# Polarfire SoC register map
Vendor: Microchip; File version: 1.0
CPU: Microchip PolarFire SoC 1.0, little endian
Registers are 32-bit, read-write, reset 0x0 unless marked. A register's access mark holds for its fields unless they carry their own. Offsets are from the block's base; [hi:lo] are bit positions; {n}, {i} and the like mark numbered series; 'fields as' and 'values as' point back to an identical list.

## GEM_A_LO (part 8 of 8) — GEM_A_LO Controller
Base 0x20110000
Same registers: GEM_B_LO 0x20112000, GEM_A_HI 0x28110000, GEM_B_HI 0x28112000
0x11EC emac_tsu_ptp_rx_nsec ro — PTP Event Frame Received Nanoseconds Register
  [29:0] TIMER — PTP Event Frame Received Nanoseconds. The register is updated with the value that the 1588 timer nanoseconds register held when the SFD of a PTP receive primary event crosses the MII interface. The actual update occurs when the GEM recognizes the frame as a PTP sync or delay_req frame. An interrupt is issued when the register is updated.
0x11F0 emac_tsu_peer_tx_sec ro — PTP Peer Event Frame Transmitted Seconds Register 31:0
  [31:0] TIMER — PTP Peer Event Frame Received Seconds. The register is updated with the value that the 1588 timer seconds register held when the SFD of a PTP transmit peer event crosses the MII interface. The actual update occurs when the GEM recognizes the frame as a PTP pdelay_req or pdelay_resp frame. An interrupt is issued when the register is updated.
0x11F4 emac_tsu_peer_tx_nsec ro — PTP Peer Event Frame Transmitted Nanoseconds Register
  [29:0] TIMER — PTP Peer Event Frame Transmitted Nanoseconds. The register is updated with the value that the 1588 timer nanoseconds register held when the SFD of a PTP transmit peer event crosses the MII interface. The actual update occurs when the GEM recognizes the frame as a PTP pdelay_req or pdelay_resp frame. An interrupt is issued when the register is updated.
0x11F8 emac_tsu_peer_rx_sec ro — PTP Peer Event Frame Received Seconds Register 31:0
  [31:0] TIMER — PTP Peer Event Frame Received Seconds. The register is updated with the value that the 1588 timer seconds register held when the SFD of a PTP receive peer event crosses the MII interface. The actual update occurs when the GEM recognizes the frame as a PTP pdelay_req or pdelay_resp frame. An interrupt is issued when the register is updated.
0x11FC emac_tsu_peer_rx_nsec ro — PTP Peer Event Frame Received Nanoseconds Register
  [29:0] TIMER — PTP Peer Event Frame Received Nanoseconds. The register is updated with the value that the 1588 timer nanoseconds register held when the SFD of a PTP receive peer event crosses the MII interface. The actual update occurs when the GEM recognizes the frame as a PTP pdelay_req or pdelay_resp frame. An interrupt is issued when the register is updated.
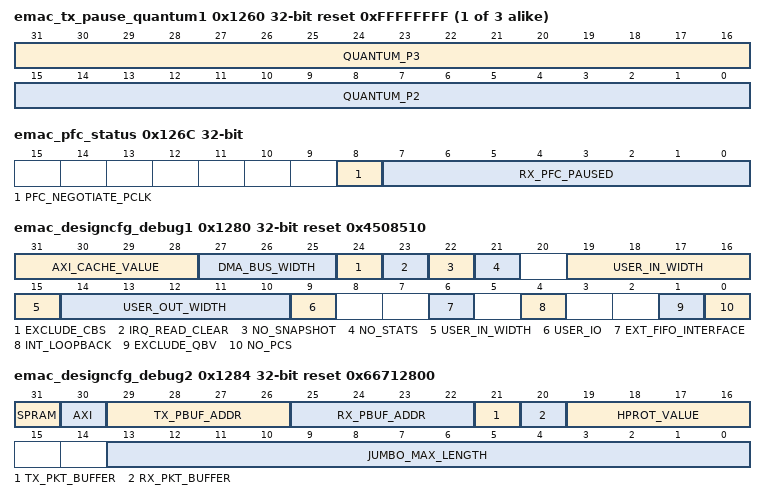
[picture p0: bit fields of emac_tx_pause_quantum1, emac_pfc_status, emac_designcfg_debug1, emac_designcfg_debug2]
{0x125C+4i} emac_tx_pause_quantum{i} reset 0xFFFFFFFF (i=1..3) — Transmit Pause Quantum Register {i}
  [31:16] QUANTUM_P{2i+1} — Transmit pause quantum - written with the pause quantum value for pause frame transmission of priority {2i+1}.
  [15:0] QUANTUM_P{2i} — Transmit pause quantum - written with the pause quantum value for pause frame transmission of priority {2i}.
0x126C emac_pfc_status ro — Priority Flow Control status register - indicates whether PFC has been negotiated and the current state of the PFC counters for each priority.
  [8] PFC_NEGOTIATE_PCLK — Set when PFC Priority Based Pause has been negotiated.
  [7:0] RX_PFC_PAUSED — Reflects the state of the rx_pfc_paused signals. Each bit in the vector corresponds to a priority indicated within the received PFC priority based pause frame. A bit is set when a PFC priority based pause frame has been received, and the associated priority pause time quantum is non-zero. The bit is cleared when the associated pause time has elapsed.
0x1270 emac_rx_lpi ro — Received LPI transitions
  [15:0] COUNT rw — Count of RX LPI transitions. A count of the number of times there is a transition from receiving normal idle to receiving low power idle. Cleared on read.
0x1274 emac_rx_lpi_time ro — Received LPI time
  [23:0] LPI_TIME rw — Time in LPI. This register increments once every 16 pclk cycles when the LPI indication bit 7 is set in the network status register. Cleared on read.
0x1278 emac_tx_lpi ro — Transmit LPI transitions
  [15:0] COUNT rw — Count of TX LPI transmissions. A count of the number of times the enable LPI transmission bit 19 goes from low to high in the network control register. Cleared on read.
0x127C emac_tx_lpi_time ro — Transmit LPI time
  [23:0] LPI_TIME rw — Time in LPI. This register increments once every 16 pclk cycles when the enable LPI transmission bit 19 is set in the network control register. Cleared on read.
0x1280 emac_designcfg_debug1 ro reset 0x4508510 — Design Configuration Register 1 - The GEM has many parameterisation options to configure the IP during compilation stage. This is achieved using Verilog define compiler directives in an include file called gem_defs.v. This configuration is readable through APB addressable designcfg_debug registers.
  [31:28] AXI_CACHE_VALUE — Takes the value of the 'gem_axi_awcache_value DEFINE
  [27:25] DMA_BUS_WIDTH — Takes the value of bits 7:5 of the 'gem_dma_bus_width DEFINE. So if the define is set to decimal 64 this will return binary 010.
  [24] EXCLUDE_CBS — Takes the value of the 'gem_exclude_cbs DEFINE.
  [23] IRQ_READ_CLEAR — Takes the value of the 'gem_irq_read_clear DEFINE
  [22] NO_SNAPSHOT — Takes the value of the 'gem_no_snapshot DEFINE
  [21] NO_STATS — Takes the value of the 'gem_no_stats DEFINE
  [19:15] USER_IN_WIDTH — Takes the value of the 'gem_user_in_width DEFINE or 1 if user_io not defined
  [14:10] USER_OUT_WIDTH — Takes the value of the 'gem_user_out_width DEFINE or 1 if user_io not defined
  [9] USER_IO — user_io not defined for the eMAC
  [6] EXT_FIFO_INTERFACE — Takes the value of the 'gem_ext_fifo_interface DEFINE
  [4] INT_LOOPBACK — Takes the value of the 'gem_int_loopback DEFINE
  [1] EXCLUDE_QBV — Takes the value of the 'gem_exclude_qbv DEFINE
  [0] NO_PCS — Takes the value of the 'gem_no_pcs DEFINE
0x1284 emac_designcfg_debug2 ro reset 0x66712800 — Design Configuration Register 2
  [31] SPRAM — Takes the value of the 'gem_spram DEFINE
  [30] AXI — Takes the value of the 'gem_axi DEFINE
  [29:26] TX_PBUF_ADDR — Takes the value of the 'gem_emac_tx_pbuf_addr DEFINE or zero if pbuf_address is decimal 16
  [25:22] RX_PBUF_ADDR — Takes the value of the 'gem_emac_rx_pbuf_addr DEFINE or zero if pbuf_address is decimal 16
  [21] TX_PKT_BUFFER — Takes the value of the 'gem_tx_pkt_buffer DEFINE
  [20] RX_PKT_BUFFER — Takes the value of the 'gem_rx_pkt_buffer DEFINE
  [19:16] HPROT_VALUE — Takes the value of the 'gem_hprot_value DEFINE
  [13:0] JUMBO_MAX_LENGTH — Takes the value of the 'gem_jumbo_max_length DEFINE
0x1288 emac_designcfg_debug3 ro reset 0x4000000 — Design Configuration Register 3
  [29:24] NUM_SPEC_ADD_FILTERS — Takes the value of the 'num_spec_add_filters DEFINE
0x128C emac_designcfg_debug4 ro — Design Configuration Register 4
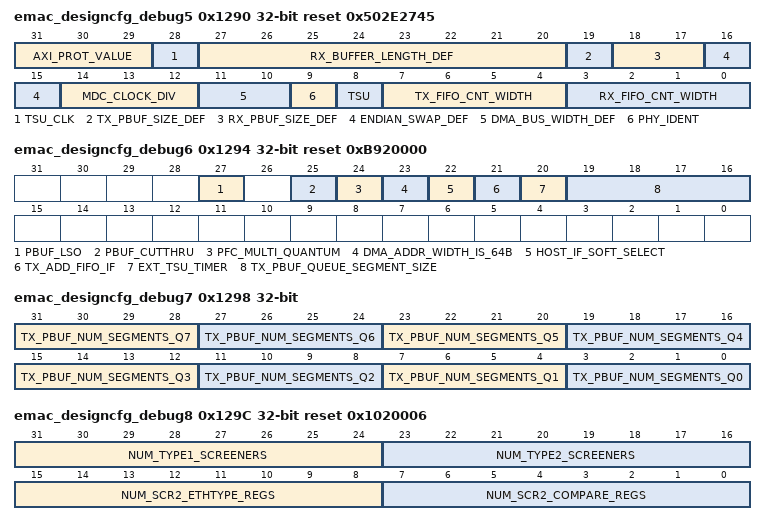
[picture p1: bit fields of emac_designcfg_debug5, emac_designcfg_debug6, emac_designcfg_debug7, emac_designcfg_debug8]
0x1290 emac_designcfg_debug5 ro reset 0x502E2745 — Design Configuration Register 5
  [31:29] AXI_PROT_VALUE — Takes the value of the edma_axi_prot_value parameter which is set by the 'gem_axi_prot_value DEFINE but will be zero if the FIFO interface has been configured
  [28] TSU_CLK — Takes the value of the 'gem_tsu_clk DEFINE
  [27:20] RX_BUFFER_LENGTH_DEF — Takes the value of the 'gem_rx_buffer_length_def DEFINE
  [19] TX_PBUF_SIZE_DEF — Takes the value of the edma_tx_pbuf_size_def parameter which is set by the 'gem_tx_pbuf_size_def DEFINE but will be zero if the FIFO inteface has been configured
  [18:17] RX_PBUF_SIZE_DEF — Takes the value of the 'gem_rx_pbuf_size_def DEFINE
  [16:15] ENDIAN_SWAP_DEF — Takes the value of the 'gem_endian_swap_def DEFINE
  [14:12] MDC_CLOCK_DIV — Takes the value of the 'gem_mdc_clock_div DEFINE
  [11:10] DMA_BUS_WIDTH_DEF — Takes the value of the 'gem_dma_bus_width_def DEFINE
  [9] PHY_IDENT — Indicates whether the top and bottom PHY_ID registers are present in the address map
  [8] TSU — Takes the value of the 'gem_tsu DEFINE
  [7:4] TX_FIFO_CNT_WIDTH — Takes the value of the 'gem_tx_fifo_cnt_width DEFINE
  [3:0] RX_FIFO_CNT_WIDTH — Takes the value of the 'gem_rx_fifo_cnt_width DEFINE
0x1294 emac_designcfg_debug6 ro reset 0xB920000 — Design Configuration Register 6
  [27] PBUF_LSO — Takes the value of the 'gem_pbuf_lso DEFINE
  [25] PBUF_CUTTHRU — Takes the value of the 'gem_pbuf_cutthru DEFINE
  [24] PFC_MULTI_QUANTUM — Takes the value of the 'gem_pfc_multi_quantum DEFINE
  [23] DMA_ADDR_WIDTH_IS_64B — Takes the value of the 'gem_dma_addr_width_is_64b DEFINE
  [22] HOST_IF_SOFT_SELECT — Takes the value of the 'gem_host_if_soft_select DEFINE
  [21] TX_ADD_FIFO_IF — Takes the value of the 'gem_tx_add_fifo_if DEFINE
  [20] EXT_TSU_TIMER — Set to one to indicate external TSU
  [19:16] TX_PBUF_QUEUE_SEGMENT_SIZE — Takes the value of the 'gem_tx_pbuf_queue_segment_size DEFINE
0x1298 emac_designcfg_debug7 ro — Design Configuration Register 7
  [4n+3:4n] TX_PBUF_NUM_SEGMENTS_Q{n} (n=1..7) — Takes the value of the 'gem_tx_pbuf_num_segments_q{n} DEFINE
  [3:0] TX_PBUF_NUM_SEGMENTS_Q0 — Takes the value of the edma_tx_pbuf_num_segments_q0 parameter which is set by the 'gem_tx_pbuf_num_segments_q0 DEFINE or is zero if priority queuing is not configured.
0x129C emac_designcfg_debug8 ro reset 0x1020006 — Design Configuration Register 8
  [31:24] NUM_TYPE1_SCREENERS — Set to 1 for the eMAC (express MAC)
  [23:16] NUM_TYPE2_SCREENERS — Set to 2 for the eMAC (express MAC)
  [15:8] NUM_SCR2_ETHTYPE_REGS — Set to 0 for the eMAC (express MAC)
  [7:0] NUM_SCR2_COMPARE_REGS — Set to 6 for the eMAC (express MAC)
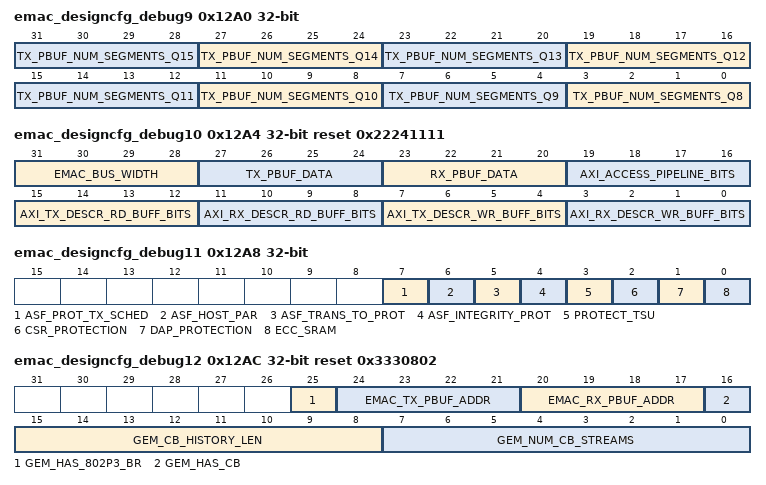
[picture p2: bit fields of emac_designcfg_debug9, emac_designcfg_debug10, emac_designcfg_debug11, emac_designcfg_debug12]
0x12A0 emac_designcfg_debug9 ro — Design Configuration Register 9
  [4n-29:4n-32] TX_PBUF_NUM_SEGMENTS_Q{n} (n=8..15) — Takes the value of the 'gem_tx_pbuf_num_segments_q{n} DEFINE
0x12A4 emac_designcfg_debug10 ro reset 0x22241111 — Design Configuration Register 10
  [31:28] EMAC_BUS_WIDTH — Takes the value of the 'gem_emac_bus_width DEFINE. 1 - The MAC has a datawidth of 32bits. 2 - The MAC has a datawidth of 64bits. 4 - The MAC has a datawidth of 128bits
  [27:24] TX_PBUF_DATA — Takes the value of the 'gem_tx_pbuf_data DEFINE. 1 - The TX DPRAM has a datawidth of 32bits. 2 - The TX DPRAM has a datawidth of 64bits. 4 - The TX DPRAM has a datawidth of 128bits
  [23:20] RX_PBUF_DATA — Takes the value of the 'gem_rx_pbuf_data DEFINE. 1 - The RX DPRAM has a datawidth of 32bits. 2 - The RX DPRAM has a datawidth of 64bits. 4 - RX The DPRAM has a datawidth of 128bits
  [19:16] AXI_ACCESS_PIPELINE_BITS — Takes the value of the edma_axi_access_pipeline_bits parameter which is set by the 'gem_axi_access_pipeline_bits DEFINE or is zero if the FIFO interface is configured.
  [15:12] AXI_TX_DESCR_RD_BUFF_BITS — Takes the value of the edma_axi_tx_descr_rd_buff_bits parameter which is set by the 'gem_axi_tx_descr_rd_buff_bits DEFINE or is zero if the FIFO interface is configured.
  [11:8] AXI_RX_DESCR_RD_BUFF_BITS — Takes the value of the edma_axi_rx_descr_rd_buff_bits parameter which is set by the 'gem_axi_rx_descr_rd_buff_bits DEFINE or is zero if the FIFO interface is configured.
  [7:4] AXI_TX_DESCR_WR_BUFF_BITS — Takes the value of the edma_axi_tx_descr_wr_buff_bits parameter which is set by the 'gem_axi_tx_descr_wr_buff_bits DEFINE or is zero if the FIFO interface is configured.
  [3:0] AXI_RX_DESCR_WR_BUFF_BITS — Takes the value of the edma_axi_rx_descr_wr_buff_bits parameter which is set by the 'gem_axi_rx_descr_wr_buff_bits DEFINE or is zero if the FIFO interface is configured.
0x12A8 emac_designcfg_debug11 ro — Design Configuration Register 11
  [7] ASF_PROT_TX_SCHED — Takes the value of the edma_asf_asf_prot_tx_sched parameter which is set by the 'gem_asf_prot_tx_sched DEFINE.
  [6] ASF_HOST_PAR — Takes the value of the edma_asf_host_par parameter which is set by the 'gem_asf_host_par DEFINE.
  [5] ASF_TRANS_TO_PROT — Takes the value of the edma_asf_trans_to_prot parameter which is set by the 'gem_asf_enable DEFINE.
  [4] ASF_INTEGRITY_PROT — Takes the value of the edma_asf_integrity_prot parameter which is set by the 'gem_asf_enable DEFINE.
  [3] PROTECT_TSU — akes the value of the edma_asf_prot_tsu parameter which is set by the 'gem_asf_prot_tsu DEFINE or is zero if no TSU is present.
  [2] CSR_PROTECTION — Takes the value of the edma_asf_csr_prot parameter which is set by the 'gem_asf_enable DEFINE.
  [1] DAP_PROTECTION — Takes the value of the edma_asf_dap_prot parameter which is set by the 'gem_asf_enable DEFINE.
  [0] ECC_SRAM — Takes the value of the edma_asf_ecc_sram parameter which is set by the 'gem_asf_ecc_sram DEFINE.
0x12AC emac_designcfg_debug12 ro reset 0x3330802 — Design Configuration Register 12
  [25] GEM_HAS_802P3_BR — A value of one indicates that gem_has_802p3_br is defined. If defined the configuration contains both an express MAC (eMAC) and a pre-emptable MAC (pMAC) to allow 802.3br frame pre-emption.
  [24:21] EMAC_TX_PBUF_ADDR — Takes the value of the 'gem_emac_tx_pbuf_addr DEFINE - this defines the size of the transmit SRAM for express MAC (eMAC) when 802.3br is configured - will be zero if emac_tx_pbuf_address is decimal 16
  [20:17] EMAC_RX_PBUF_ADDR — Takes the value of the 'gem_emac_rx_pbuf_addr DEFINE - this defines the size of the receive SRAM for express MAC (eMAC) when 802.3br is configured - will be zero if emac_tx_pbuf_address is decimal 16
  [16] GEM_HAS_CB — Indicates whether gem has 802.1CB/FRER configured
  [15:8] GEM_CB_HISTORY_LEN — Takes the value of the 'gem_seq_history_len DEFINE or 0x01 if undefined.
  [7:0] GEM_NUM_CB_STREAMS — Set to 2 for the eMAC (express MAC)
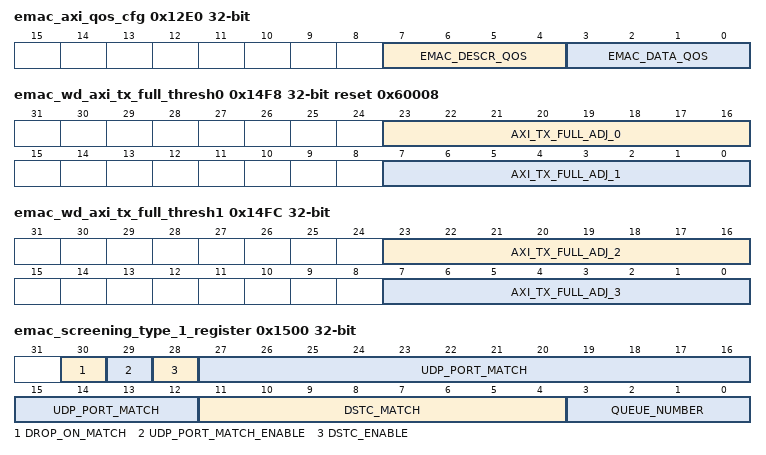
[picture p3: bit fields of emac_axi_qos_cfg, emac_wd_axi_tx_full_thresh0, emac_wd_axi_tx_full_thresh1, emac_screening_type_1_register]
0x12E0 emac_axi_qos_cfg — eMAC AXI Quality of Service register. This register is only present if AXI is configured. This register contains 8-bits to control driving of the ARQOS and AWQOS outputs (4-bits each). The lower four bits are for data accesses and the upper four bits are for descriptor accesses.
  [7:4] EMAC_DESCR_QOS — Determines what value to drive to the ARQOS and AWQOS outputs (4-bits each) for eMAC descriptor accesses.
  [3:0] EMAC_DATA_QOS — Determines what value to drive to the ARQOS and AWQOS outputs (4-bits each) for eMAC data accesses.
0x14BC emac_cbs_control — The IdleSlope value is defined as the rate of change of credit when a packet is waiting to be sent. This must not exceed the portTransmitRate which is dependent on the speed of operation, eg, portTransmitRate: 1Gb/s = 32'h07735940 (125 Mbytes/s), 100Mb/sec = 32'h017D7840 (25 Mnibbles/s), 10Mb/sec = 32'h002625A0 (2.5 Mnibbles/s). If 50% of bandwidth was to be allocated to a particular queue in 1Gb/sec mode then the IdleSlope value for that queue would be calculated as 32'h07735940/2. Note: Credit-Based Shaping should be disabled prior to updating the IdleSlope values. As another example, for a 1722 audio packet with a payload of 6 samples per channel, the packet size would be: 7 (preamble) + 1 (SFD) + 50 (packet header) + 6x4x2(payload) + 4 (CRC) = 110 bytes. For a rate of 8000 packets per second, the desired rate would 110 x 8000 bytes per second, so the programmed idleSlope value would be 880000 for a 1Gb/s connection, or 1760000 for a 100Mb/s or 10Mbs connection. See Figure 6.3 in the IEEE 1722 standard. In practice, the actual transmission rate will be vary slightly from that calculated. In this case, the idleSlope value should be recalibrated based on the variance between the measured and expected rate, and in this case very accurate transmission rates can be achieved. (The idleslope value is scaled by 2.5 in 2.5G operation and so the port transmit rate is the same for 1G and 2.5G.)
  [0] CBS_ENABLE_QUEUE_A — Enable Credit-Based Shaping on the highest priority queue (queue A). Write 1 to enable
0x14C0 emac_cbs_idleslope_q_a — Queue A is the highest priority queue. This is the highest indexed active queue, e.g. For a system with Q0 to Q7, this would be Q7 if all queues were active.
  [31:0] IDLESLOPE_A — IdleSlope value for queue A in bytes/sec for gigabit operation and nibbles/sec for 10/100 operation
0x14C4 emac_cbs_idleslope_q_b — Queue B is the 2nd highest priority queue. This is the second highest indexed active queue, e.g. For a system with Q0 to Q7, this would be Q6 if all queues were active.
  [31:0] IDLESLOPE_B — IdleSlope value for queue B in bytes/sec for gigabit operation and nibbles/sec for 10/100 operation
0x14C8 emac_upper_tx_q_base_addr — Upper 32 bits of transmit buffer descriptor queue base address.
  [31:0] UPPER_TX_Q_BASE_ADDR — Upper 32 bits of transmit buffer descriptor queue base address. Used when 64 bit addressing is enabled. (In releases earlier to 1p06f2 this register also affected the receive descriptor queue.)
0x14CC emac_tx_bd_control — Transmit buffer descriptor control register - this register determines which transmit frames, with time stamps reported in the buffer descriptor status field in extended buffer descriptor mode, set bit 23 in transmit buffer descriptor word 1.
  [5:4] TX_BD_TS_MODE — Transmit Descriptor Timestamp Insertion mode - bit 23 in transmit buffer descriptor word 1 when extended buffer descriptor mode is enabled,, : 00: Bit 23 always zero,, : 01: Bit 23 high for PTP Event Frames only,, : 10: Bit 23 high for all PTP Frames only,, : 11: Bit 23 always high
0x14D0 emac_rx_bd_control — Receive buffer descriptor control register - this register determines which receive frames have time stamps reported in the buffer descriptor status field
  [5:4] RX_BD_TS_MODE — Receive Descriptor Timestamp Insertion mode,, : 00: TS insertion disable,, : 01: TS inserted for PTP Event Frames only,, : 10: TS inserted for All PTP Frames only,, : 11: TS insertion for All Frames
0x14D4 emac_upper_rx_q_base_addr — Upper 32 bits of receive buffer descriptor queue base address.
  [31:0] UPPER_RX_Q_BASE_ADDR — Upper 32 bits of receive buffer descriptor queue base address. Used when 64 bit addressing is enabled.
0x14EC emac_wd_counter reset 0x7 — Hidden control register - do not alter
  [3:0] RX_BD_REREAD_TIMER — Controls counter used to retry receive descriptor reads (retries may occur if there was a resource error and there are frames waiting in the internal SRAM buffer to be off-loaded to host memory)
0x14F8 emac_wd_axi_tx_full_thresh0 reset 0x60008 — Hidden control register - do not alter
  [23:16] AXI_TX_FULL_ADJ_0 — AXI single port SRAM fine tuning
  [7:0] AXI_TX_FULL_ADJ_1 — AXI single port SRAM fine tuning
0x14FC emac_wd_axi_tx_full_thresh1 — Hidden control register - do not alter
  [23:16] AXI_TX_FULL_ADJ_2 — AXI single port SRAM fine tuning
  [7:0] AXI_TX_FULL_ADJ_3 — AXI single port SRAM fine tuning
0x1500 emac_screening_type_1_register — Screening type 1 registers are used to allocate up to 16 priority queues to received frames based on certain IP or UDP fields of incoming frames. Firstly, when DS/TC match enable is set (bit 28), the DS (Differentiated Services) field of the received IPv4 header or TC field (traffic class) of IPv6 headers are matched against bits 11:4. Secondly, when UDP port match enable is set (bit 29), the UDP Destination Port of the received UDP frame is matched against bits 27:12. Both UDP and DS/TC matching can be enabled simultaneously or individually. If a match is successful, then the queue value programmed in bits 3:0 is allocated to the frame. The required number of Type 1 screening registers is configured in the gem defines file. Up to 16 type 1 screening registers have been allocated APB address space between 0x500 and 0x53C. The bit mappings for these registers are as follows:
  [30] DROP_ON_MATCH — When set, if the frame matches it will be completely dropped. In this case the queue number is don't care.
  [29] UDP_PORT_MATCH_ENABLE
  [28] DSTC_ENABLE
  [27:12] UDP_PORT_MATCH
  [11:4] DSTC_MATCH
  [3:0] QUEUE_NUMBER — Queue Number (0 to 15)
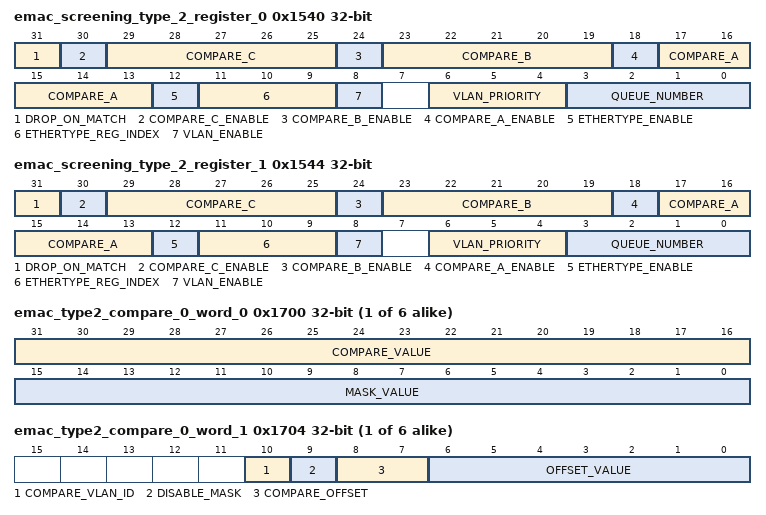
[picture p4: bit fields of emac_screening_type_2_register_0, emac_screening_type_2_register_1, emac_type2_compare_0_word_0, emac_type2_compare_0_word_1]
0x1540 emac_screening_type_2_register_0 — Screener Type 2 match registers allow a screen to be configured that is the combination of all or any of the following comparisons:, :1) An enabled VLAN Priority. A VLAN Priority match will be performed if the VLAN priority enable is set. The extracted priority field in the VLAN header is compared against 3 bits within the screener type 2 register itself., :2) An enabled EtherType., :3) An enabled Field Compare A. , :4) An enabled Field Compare B. , :5) An enabled Field Compare C. , :All enabled comparisons are ANDed together to form the overall type 2 screener match. If a match is successful, then the queue value programmed in bits 3:0 is allocated to the frame. The required number of Type 2 screening registers is configured in the gem defines file. Up to 16 type 2 screening registers have been allocated APB address space between 0x540 and 0x57C. The bit mappings for these registers are as follows:
  [31] DROP_ON_MATCH — When set, if the frame matches it will be completely dropped. In this case the queue number is don't care.
  [30] COMPARE_C_ENABLE
  [29:25] COMPARE_C — Compare C - Index to screener type 2 Compare register
  [24] COMPARE_B_ENABLE
  [23:19] COMPARE_B — Compare B - Index to screener type 2 Compare register
  [18] COMPARE_A_ENABLE
  [17:13] COMPARE_A — Compare A - Index to screener type 2 Compare register
  [12] ETHERTYPE_ENABLE
  [11:9] ETHERTYPE_REG_INDEX — Index to screener type 2 EtherType register
  [8] VLAN_ENABLE
  [6:4] VLAN_PRIORITY
  [3:0] QUEUE_NUMBER — Queue Number (0 to 15)
0x1544 emac_screening_type_2_register_1 — Screener Type 2 match registers allow a screen to be configured that is the combination of all or any of the following comparisons:, :1) An enabled VLAN Priority. A VLAN Priority match will be performed if the VLAN priority enable is set. The extracted priority field in the VLAN header is compared against 3 bits within the screener type 2 register itself., :2) An enabled EtherType., :3) An enabled Field Compare A. , :4) An enabled Field Compare B. , :5) An enabled Field Compare C. , :All enabled comparisons are ANDed together to form the overall type 2 screener match. If a match is successful, then the queue value programmed in bits 3:0 is allocated to the frame. The required number of Type 2 screening registers is configured in the gem defines file. Up to 16 type 2 screening registers have been allocated APB address space between 0x540 and 0x57C. The bit mappings for these registers are as follows:
  fields as emac_screening_type_2_register_0
0x1580 emac_tx_sched_ctrl — This register controls the transmit scheduling algorithm the user can select for the eMAC.
  [1:0] TX_SCHED — Transmit scheduling algorithm., : 00 : Normal Priority, : 01 : CBS Enabled only valid if CBS capability selected., : 10 : DWRR Enabled, : 11 : ETS Enabled
0x1590 emac_bw_rate_limit — This register holds the DWRR weighting value or the ETS bandwidth percentage value used by the transmit scheduler for the eMAC.
  [7:0] EMAC_DWRR_ETS_WEIGHT — DWRR Weighting / ETS Bandwidth Allocation for the eMAC
0x15A0 emac_tx_q_seg_alloc_q_lower — There should be no need to change this register for the eMAC.
  [2:0] SEGMENT_ALLOC — Number of segments allocated. This should be entered as a log 2, for example entering a value of 2 would grant 4 segments. A maximum of 16 segments can be granted.
{0x1700+8i} emac_type2_compare_{i}_word_0 (i=0..5) — Compare A, B and C fields of the screener type 2 match register are pointers to a pool of up to 32 compare registers. If enabled the compare is true if the data at the OFFSET into the frame, ANDed with the MASK Value if the mask is enabled, is equal to the COMPARE Value. Either a 16 bit comparison or a 32 bit comparison is done. This selection is made via the associated compare word1 register bit 9. If a 16 bit comparison is selected, then a 16 bit mask is also available to the user to select which bits should be compared. If the 32 bit compare option is selected, then no mask is available. The byte at the OFFSET number of bytes from the index start is compared thru bits 7:0 of the configured VALUE. The byte at the OFFSET number of bytes + 1 from the index start is compared thru bits 15:8 of the configured VALUE and so on. The OFFSET can be configured to be from 0 to 127 bytes from either the start of the frame, the byte following the therType field (last EtherType in the header if the frame is VLAN tagged), the byte following the IP header (IPv4 or IPv6) or from the byte following the start of the TCP/UDP header. The required number of Type 2 screening registers up to a maximum of 32 is configurable in the gem defines file and have been allocated APB address space between 0x700 and 0x7fc. Note. when using RX Partial Store and Forward mode and priority queues, the frame offset must be less than the Partial Store and Forward watermark. If the offset is higher than the watermark value it's not possible to identify the priority queue before the frame is sent to the AMBA interface, and an incorrect priority queue may be used.
  [31:16] COMPARE_VALUE — 2 byte Compare Value., :, :If bit 9 of the associated compare_word1 register is set, then the byte stored in bits [23:16] is compared against the byte in the received frame from the selected offset+2 and the byte stored in bits [31:24] is compared against the byte in the received frame from the selected offset+3., :, :If bit 9 of the associated compare_word1 register is clear, then the byte stored in bits [23:16] is compared against the byte in the received frame from the selected offset+0 and the byte stored in bits [31:24] is compared against the byte in the received frame from the selected offset+1., :
  [15:0] MASK_VALUE — These bits can be either a 2 byte mask field or an additional 2 byte Compare Value. , :, :If bit 9 of the associated compare_word1 register is set, then the byte stored in bits [7:0] is compared against the byte in the received frame from the selected offset+0 and the byte stored in bits [15:8] is compared against the byte in the received frame from the selected offset+1. , :, :If bit 9 of the associated compare_word1 register is clear, these bits become a direct 2-byte mask for the 2-byte compare register in bits [31:16]. A value of zero in a mask bit masks the corresponding data bit, a value of 1 enables the comparison.
{0x1704+8i} emac_type2_compare_{i}_word_1 (i=0..5) — Type2 Compare Word 1
  [10] COMPARE_VLAN_ID — If set bits 9, 8 and 6:0 must be 0 and bit 7 of compare_offset is used as follows:, :0 Compare C-TAG VID (VLAN has EtherType of 0x8100), :1 Compare S-TAG VID comparison (VLAN has EtherType of the value in the stacked VLAN register at 0x00C0), :Note the byte order is such that if 81 00 00 20 is received to indicate a C-TAG frame with VID 020 0x00200FFF would be written to the compare register. So in the special case of VLAN comparison the last byte received is the least significant byte in the compare register
  [9] DISABLE_MASK — This bit is used to control whether the compare register word_0 contains a 4-byte compare value, or a 2-byte compare value with a 2-byte mask value., :1 - 4-byte compare value, :0 - 2-byte compare, 2-byte mask
  [8:7] COMPARE_OFFSET — Compare byte offset., :00 : Offset from beginning of the frame., :01 : Offset from byte after Ether Type., :10 : Offset from byte following end of IP header., :11 : Offset from byte following end of TCP/UDP header
  [6:0] OFFSET_VALUE — Offset value in bytes
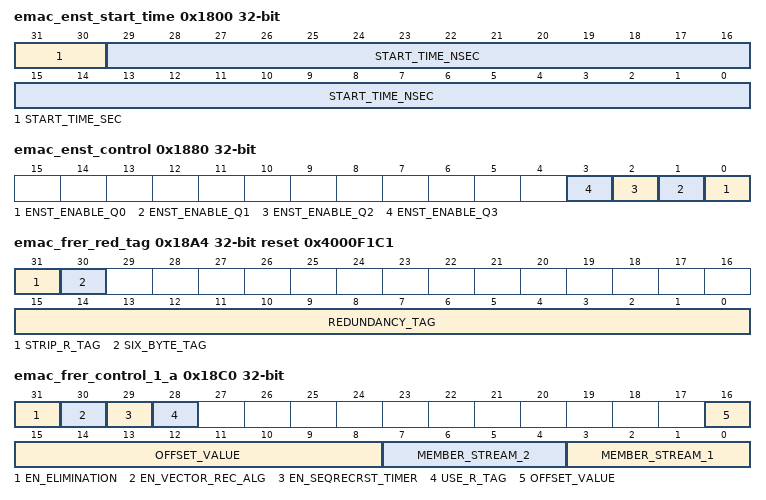
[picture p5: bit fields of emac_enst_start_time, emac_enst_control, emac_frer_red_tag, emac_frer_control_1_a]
0x1800 emac_enst_start_time — This register sets the absolute time at which queue q0 starts EnST transmit scheduling
  [31:30] START_TIME_SEC — Bits 31:30 of the start time (seconds field), for q0
  [29:0] START_TIME_NSEC — Bits 29:0 of the start time (nanoseconds field), for q0
0x1820 emac_enst_on_time reset 0x1FFFF — This register sets the time period for which queue q0 is to be open, (on_time_nsec), this register has to be written according to the speed mode as:, : ||1Gbps or 2.5Gbps|| : on_time = on_time_nsec/8, : ||100Mbps|| : on_time = on_time_nsec/80, : ||10Mbps|| : on_time = on_time_nsec/800
  [16:0] ON_TIME — on_time, for q0
0x1840 emac_enst_off_time — This register sets the time period for which queue q0 is to be blocked, (off_time_nsec), this register has to be written according to the speed mode as:, : ||1Gbps or 2.5Gbps|| => off_time = off_time_nsec/8, : ||100Mbps|| => off_time = off_time_nsec/80, : ||10Mbps|| => off_time = off_time_nsec/800
  [16:0] OFF_TIME — Off_time, for q0
0x1880 emac_enst_control — Enhancement for Scheduled Traffic control register. EnST scheduling can only be applied to a maximum number of 8 queues. If 802.3br operation has been configured and both an eMAC and pMAC are present then the eMAC only supports a single queue and EnST is enabled on the eMAC by writing to bit 0 of emac_enst_control.
  [n] ENST_ENABLE_Q{n} (n=0..3) — Set to enable enhanced scheduler traffic (ENST), for q{n}
0x18A0 emac_frer_timeout — FRER timeout register. This determines when the sequence recovery reset timers are reset and is used by all of the configured CB streams. It is programmed as a count of 8192 rx_clk periods. 8192 rx_clk periods is 65.536 microseconds at gigabit speeds and 327.68 microseconds at 100M speeds, this allows a max timeout value of about 4 seconds at gigabit speeds - for test purposes if bit 12 (retry_test) is set in the network configuration register at 0x004 then the timeout value just becomes a count of rx_clk periods (ie a speed-up of 8192 in the time-out process).
  [15:0] TIMEOUT — Count of 8192 rx_clk periods.
0x18A4 emac_frer_red_tag reset 0x4000F1C1 — FRER redundancy tag register. This defines the Ethertype used to identify the R-TAG (redundancy tag) and contains a control bit to enable stripping of the R-TAG from received frames. IEEE 802.1CB has defined the value of this Ethertype to be 0xF1C1. Whether or not a particular stream uses the redundancy tag to locate the sequence number is determined by bit 28 in that streams control register.
  [31] STRIP_R_TAG — If set the redundancy tag is stripped from received frames. If this bit is set then the receive octet counters reflect post deletion frame size so the FRER functionality is transparent to higher level management if the stripping function is enabled. If the statistics counters need to reflect the actual number of octets received, then the stripping functionality should be disabled.
  [30] SIX_BYTE_TAG — Draft 2.4 and earlier drafts of the 802.1CB standard defined a four-byte redundancy tag. Drafts 2.5 and later specified a six-byte tag. Releases 1p10 and 1p11 were implemented in accordance with draft 2.4 of the standard. Set this bit to zero to inter-operate with implementations that use a four-byte tag.
  [15:0] REDUNDANCY_TAG — Ethertype value used to identify the redundancy tag (R-TAG).
0x18C0 emac_frer_control_1_a — FRER control register A
  [31] EN_ELIMINATION — Enable 802.1CB elimination of received frames
  [30] EN_VECTOR_REC_ALG — Enable 802.1CB vector recovery algorithm, : 0 enables the match recovery algorithm, : 1 enables the vector recovery algorithm, :This bit should only be changed when bit 31 en_elimination is low
  [29] EN_SEQRECRST_TIMER — Enable 802.1CB sequence recovery reset timer - this bit may be changed when bit 31 en_elimination is low
  [28] USE_R_TAG — Set to one to use redundancy tag to identify sequence number otherwise use offset value to identify bottom of sequence number - this bit should only be changed when bit 31 en_elimination is low
  [16:8] OFFSET_VALUE — Offset value in bytes from the start packet delimiter to the most significant byte of the 802.1CB sequence number - 9 bits allow a maximum value of 511 - allowing a TCP sequence number to be used with IPv6 - this bit should only be changed when en_elimination is low
  [7:4] MEMBER_STREAM_2 — Pointer to screener type 2 register used for member stream identification. The member stream 1 and 2 values may be programmed to identical values. - this bit should only be changed when en_elimination is low
  [3:0] MEMBER_STREAM_1 — Pointer to screener type 2 register used for member stream identification. The member stream 1 and 2 values may be programmed to identical values. - this bit should only be changed when en_elimination is low
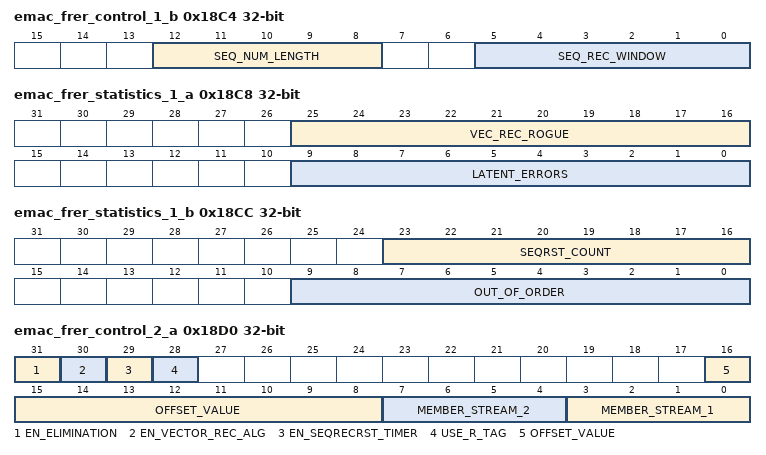
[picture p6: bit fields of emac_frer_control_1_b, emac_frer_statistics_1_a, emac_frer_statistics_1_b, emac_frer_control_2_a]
0x18C4 emac_frer_control_1_b — FRER control register B. This register has default values where the sequence number length defaults to 16 and the vector recovery window defaults to the size of the history vector. It is not expected that the user will need to change these default values.
  [12:8] SEQ_NUM_LENGTH — Number of significant bits of the 802.1CB sequence number. The value 0x00 or numbers greater than 16 bits are equivalent to 16, but the number written will still be read back if it is greater than 16. If a value of less than 16 is written, then the sequence recovery algorithm will only consider that number of LSBs of the sequence number. The minimum size of seq_num_length has to be such that 2^seq_num_len is at least 2xgem_seq_history_len otherwise the vector recovery algorithm will not work correctly - this bit should only be changed when en_elimination is low
  [5:0] SEQ_REC_WINDOW — Vector recovery window, defines the window size used by the vector recovery algorithm to determine whether to reject a packet. Six bits allow a window size of 63, for effective operation of FRER users should not write a value greater than the gem_seq_history_len configuration define, a value of zero means the entire history vector is used - this bit should only be changed when en_elimination is low.
0x18C8 emac_frer_statistics_1_a ro — FRER statistics register A. This register is cleared on a read and does not roll over if its maximum value is reached.
  [25:16] VEC_REC_ROGUE rw — Count of number of frames dropped by the vector recovery algorithm for being out of range
  [9:0] LATENT_ERRORS rw — Count of sequence numbers seen without a duplicate. The latent error count is updated when a frame is dropped from the history vector. So the update only happens after a new frame is received.
0x18CC emac_frer_statistics_1_b ro — FRER statistics register B. This register is cleared on a read and does not roll over if its maximum value is reached.
  [23:16] SEQRST_COUNT rw — Count of number of times the sequence recovery reset timer decrements to zero.
  [9:0] OUT_OF_ORDER rw — Count of out of order sequence numbers received. Incremented when a frame is accepted but the sequence number is not +1 of the highest stored value.
0x18D0 emac_frer_control_2_a — FRER control register A
  fields as emac_frer_control_1_a
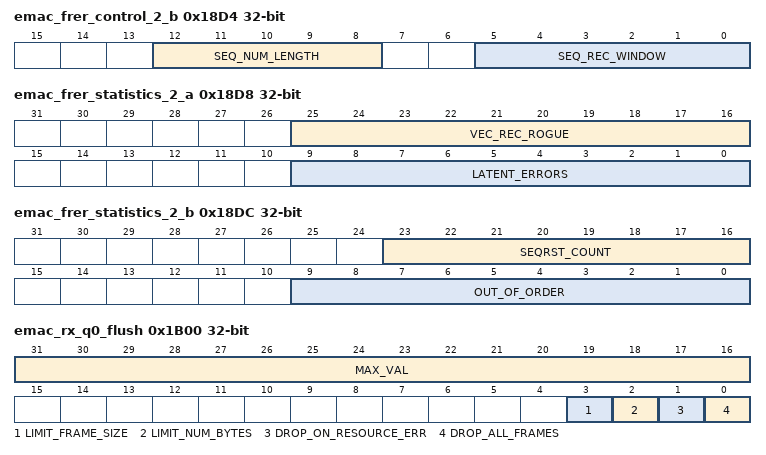
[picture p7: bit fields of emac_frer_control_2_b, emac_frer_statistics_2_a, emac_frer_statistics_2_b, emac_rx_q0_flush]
0x18D4 emac_frer_control_2_b — FRER control register B. This register has default values where the sequence number length defaults to 16 and the vector recovery window defaults to the size of the history vector. It is not expected that the user will need to change these default values.
  fields as emac_frer_control_1_b
0x18D8 emac_frer_statistics_2_a ro — FRER statistics register A. This register is cleared on a read and does not roll over if its maximum value is reached.
  fields as emac_frer_statistics_1_a
0x18DC emac_frer_statistics_2_b ro — FRER statistics register B. This register is cleared on a read and does not roll over if its maximum value is reached.
  fields as emac_frer_statistics_1_b
0x1B00 emac_rx_q0_flush — Receive Queue flush register. This register defines the traffic policing mode of operation. Each mode can be set simultaneously with the exception of bits 2 and 3, which are exclusive. If bits 2 and 3 are both set then only bit 3 is treated as active.
  [31:16] MAX_VAL — This 16 bit vector is used when either bit 2 or 3 of this register is asserted. Refer to the description in those bits for details.
  [3] LIMIT_FRAME_SIZE — When set max_val (bits 31:16) indicates the maximum frame-length in bytes that may be received. Frames exceeding this length will be dropped. This traffic policing function is relevant to the 802.1Qci standard which specifies stream filtering based on a maximum SDU (service data unit) size.
  [2] LIMIT_NUM_BYTES — When set, the number of 128 byte chunks of data received for this queue and already stored in the SRAM awaiting DMA memory writes cannot exceed max_val (bits 31:16).
  [1] DROP_ON_RESOURCE_ERR — When set, if a free DMA descriptor for this queue cannot be obtained (also referred to as lack of descriptor resource and occurs when the software either cannot free up descriptors quickly enough to meet the receive traffic rate or has deliberately decided not to free any descriptors), all new frames received on this queue will be automatically discarded.
  [0] DROP_ALL_FRAMES — When set, all frames on this queue will be dropped.
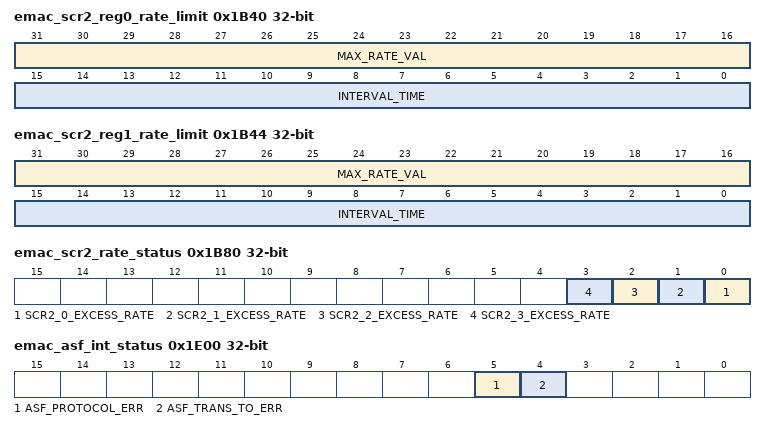
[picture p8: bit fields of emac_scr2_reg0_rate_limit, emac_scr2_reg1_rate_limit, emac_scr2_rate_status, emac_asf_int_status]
0x1B40 emac_scr2_reg0_rate_limit — Screener type 2 maximum rate register. This register defines the maximum receive rate for the corresponding type 2 screener. This is a traffic policing function and is relevant to the 802.1Qci standard. If the maximum rate is exceeded all frames matched by the corresponding type 2 screener will be discarded until the receive rate falls below the specified value.
  [31:16] MAX_RATE_VAL — This is the maximum number of bytes this screener is permitted to match in the programmed interval time.
  [15:0] INTERVAL_TIME — If during the interval time the total number of bytes of received frames matched by the screener exceeds max_rate_val then the current frame and frames subsequently matched will dropped until an interval time passes where max_rate_val is not exceeded. If this value is set to zero, then no rate limiting will be performed. The interval time is specified in units of 64 rx_clk periods.
0x1B44 emac_scr2_reg1_rate_limit — Screener type 2 maximum rate register. This register defines the maximum receive rate for the corresponding type 2 screener. This is a traffic policing function and is relevant to the 802.1Qci standard. If the maximum rate is exceeded all frames matched by the corresponding type 2 screener will be discarded until the receive rate falls below the specified value.
  fields as emac_scr2_reg0_rate_limit
0x1B80 emac_scr2_rate_status ro — Screener rate limit exceeded status register. For each screener type 2 register configured a status bit will be set and cleared on read if the maximum receive rate is exceeded.
  [n] SCR2_{n}_EXCESS_RATE rw (n=0..3) — Set to 1 if screeners rate limiting mechanism has been triggered
0x1E00 emac_asf_int_status — ASF Interrupt Status Register. This register indicates the source of ASF interrupts. The corresponding bit in the mask register must be clear for a bit to be set. If any bit is set in this register the asf_fatal or asf_nonfatal signal will be asserted. Writing to either raw or masked status registers, clear both registers. For test purposes, trigger signal interrupt event by writing to the ASF interrupt status test register.
  [5] ASF_PROTOCOL_ERR — Protocol error interrupt
  [4] ASF_TRANS_TO_ERR — Transaction timeouts error interrupt
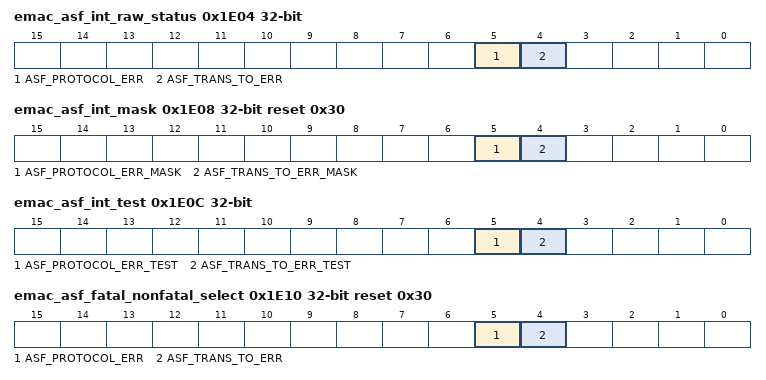
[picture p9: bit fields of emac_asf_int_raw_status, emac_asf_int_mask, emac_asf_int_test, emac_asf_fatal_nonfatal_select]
0x1E04 emac_asf_int_raw_status — ASF Interrupt Status Register. This register indicates the source of ASF interrupts. The corresponding bit in the mask register must be clear for a bit to be set. If any bit is set in this register the asf_fatal or asf_nonfatal signal will be asserted. Writing to either raw or masked status registers, clear both registers. For test purposes, trigger signal interrupt event by writing to the ASF interrupt status test register.
  fields as emac_asf_int_status
0x1E08 emac_asf_int_mask reset 0x30 — The ASF interrupt mask register indicating which interrupt bits in the ASF interrupt status register are masked. All bits are set at reset. Clear the individual bit to enable the corresponding interrupt.
  [5] ASF_PROTOCOL_ERR_MASK — Mask bit for protocol error interrupt.
  [4] ASF_TRANS_TO_ERR_MASK — Mask bit for transaction timeouts error interrupt.
0x1E0C emac_asf_int_test — The ASF interrupt test register emulate hardware even. Write one to individual bit to trigger single event in (masked and raw) status registers according to mask and will generate interrupt accordingly.
  [5] ASF_PROTOCOL_ERR_TEST — Test bit for protocol error interrupt.
  [4] ASF_TRANS_TO_ERR_TEST — Test bit for transaction timeouts error interrupt.
0x1E10 emac_asf_fatal_nonfatal_select reset 0x30 — The fatal or non-fatal interrupt register selects whether a fatal (asf_int_fatal) or non-fatal (asf_int_nonfatal) interrupt is triggered. If the bit of the event will be set to one then fatal interrupt (asf_int_fatal) will be triggered. Otherwise the non-fatal interrupt (asf_int_nonfatal) will be triggered.
  [5] ASF_PROTOCOL_ERR — Enable protocol error interrupt as fatal.
  [4] ASF_TRANS_TO_ERR — Enable transaction timeouts error interrupt as fatal.
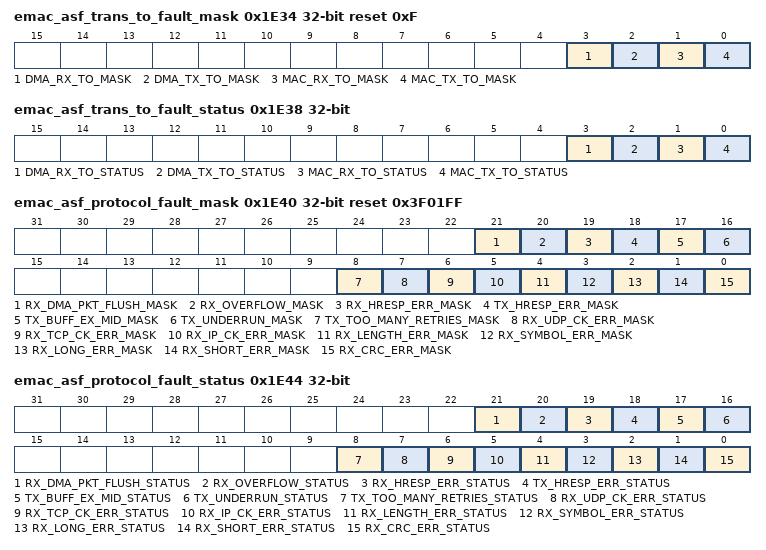
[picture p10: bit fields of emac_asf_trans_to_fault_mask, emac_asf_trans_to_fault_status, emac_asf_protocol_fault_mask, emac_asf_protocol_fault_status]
0x1E34 emac_asf_trans_to_fault_mask reset 0xF — Control register to mask out ASF transaction timeout faults from triggering interrupts. On reset, all bits are set to mask out all sources. Clear the corresponding bit to enable the interrupt source.
  [3] DMA_RX_TO_MASK — Mask register for DMA RX lockup detection.
  [2] DMA_TX_TO_MASK — Mask register for DMA TX lockup detection.
  [1] MAC_RX_TO_MASK — Mask register for MAC RX lockup detection.
  [0] MAC_TX_TO_MASK — Mask register for MAC TX lockup detection.
0x1E38 emac_asf_trans_to_fault_status — Status register for transaction timeouts fault. If a fault occurs the revelant status bit will be set to 1. Each bit can be cleared by software writing 1 to each bit.
  [3] DMA_RX_TO_STATUS — Status bit for DMA RX lockup detection.
  [2] DMA_TX_TO_STATUS — Status bit for DMA TX lockup detection.
  [1] MAC_RX_TO_STATUS — Status bit for MAC RX lockup detection.
  [0] MAC_TX_TO_STATUS — Status bit for MAC TX lockup detection.
0x1E40 emac_asf_protocol_fault_mask reset 0x3F01FF — Control register to mask out ASF Protocol faults from triggering interrupts. On reset, all bits are set to mask out all sources. Clear the corresponding bit to enable the interrupt source.
  [21] RX_DMA_PKT_FLUSH_MASK — Mask bit for RX packet was flushed from the DMA.
  [20] RX_OVERFLOW_MASK — Mask bit for DMA buffer overflow and packet was dropped.
  [19] RX_HRESP_ERR_MASK — Mask bit for DMA hresp error (AHB only).
  [18] TX_HRESP_ERR_MASK — Mask bit for DMA hresp error (AHB only).
  [17] TX_BUFF_EX_MID_MASK — Mask bit for Transmit buffers exhausted before end of packet.
  [16] TX_UNDERRUN_MASK — Mask bit for Transmit DMA underrun occurred.
  [8] TX_TOO_MANY_RETRIES_MASK — Mask bit for too many retry attempts after collision error (half duplex only).
  [7] RX_UDP_CK_ERR_MASK — Mask bit for RX packet UDP checksum error.
  [6] RX_TCP_CK_ERR_MASK — Mask bit for RX packet TCP checksum error.
  [5] RX_IP_CK_ERR_MASK — Mask bit for RX packet IP checksum error.
  [4] RX_LENGTH_ERR_MASK — Mask bit for RX packet with length field error.
  [3] RX_SYMBOL_ERR_MASK — Mask bit for RX packet with symbol errors.
  [2] RX_LONG_ERR_MASK — Mask bit for RX packet too long.
  [1] RX_SHORT_ERR_MASK — Mask bit for RX packet too short.
  [0] RX_CRC_ERR_MASK — Mask bit for RX packet with bad CRC.
0x1E44 emac_asf_protocol_fault_status — Status register for protocol faults. If a fault occurs the revelant status bit will be set to 1. Each bit can be cleared by software writing 1 to each bit
  [21] RX_DMA_PKT_FLUSH_STATUS — Status bit for RX packet was flushed from the DMA.
  [20] RX_OVERFLOW_STATUS — Status bit for DMA buffer overflow and packet was dropped.
  [19] RX_HRESP_ERR_STATUS — Status bit for DMA hresp error (AHB only).
  [18] TX_HRESP_ERR_STATUS — Status bit for DMA hresp error (AHB only).
  [17] TX_BUFF_EX_MID_STATUS — Status bit for Transmit buffers exhausted before end of packet.
  [16] TX_UNDERRUN_STATUS — Status bit for Transmit DMA underrun occurred.
  [8] TX_TOO_MANY_RETRIES_STATUS — Status bit for too many retry attempts after collision error (half duplex only).
  [7] RX_UDP_CK_ERR_STATUS — Status bit for RX packet UDP checksum error.
  [6] RX_TCP_CK_ERR_STATUS — Status bit for RX packet TCP checksum error.
  [5] RX_IP_CK_ERR_STATUS — Status bit for RX packet IP checksum error.
  [4] RX_LENGTH_ERR_STATUS — Status bit for RX packet with length field error.
  [3] RX_SYMBOL_ERR_STATUS — Status bit for RX packet with symbol errors.
  [2] RX_LONG_ERR_STATUS — Status bit for RX packet too long.
  [1] RX_SHORT_ERR_STATUS — Status bit for RX packet too short.
  [0] RX_CRC_ERR_STATUS — Status bit for RX packet with bad CRC.
